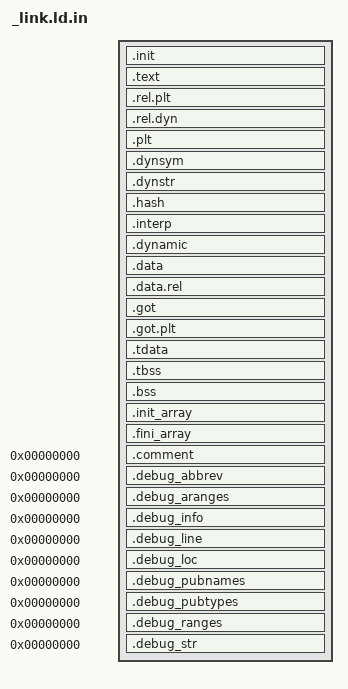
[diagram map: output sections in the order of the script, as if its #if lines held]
#ifndef SHLIB
ENTRY(_start)
#endif

PHDRS {
#if defined(DLEXE)
	interp PT_INTERP;
#endif
	text PT_LOAD FILEHDR PHDRS FLAGS(5);
	data PT_LOAD FLAGS(6);
	tls PT_TLS;
#if defined(SHLIB) || defined(DLEXE)
	dynamic PT_DYNAMIC;
#endif
	debug PT_NOTE;
}

SECTIONS {
#ifdef SHLIB
	. = SEGMENT_START("text-segment", 0);
#else
	. = SEGMENT_START("text-segment", 0x400000);
	PROVIDE (__executable_start = .);
#endif
	. = . + SIZEOF_HEADERS;

	.init : {
		*(.init);
	} :text

	.text : {
		*(.text .text.*);
		*(.rodata .rodata.*);
	} :text

#if defined(SHLIB) || defined(DLEXE)
	.rel.plt : {
		*(.rel.plt);
	}
	/*
	 *.rel.dyn MUST FOLLOW IMMEDIATELY after .rel.plt
	 * without alignment gap or DT_REL will be broken
	 */
	.rel.dyn : {
		*(.rel.*);
	} :text

	.plt : {
		*(.plt);
	} :text

	.dynsym : {
		*(.dynsym);
	} :text

	.dynstr : {
		*(.dynstr);
	} :text

	.hash : {
		*(.hash .gnu.hash);
	} :text
#endif

#if defined(DLEXE)
	.interp : {
		*(.interp);
	} :interp :text
#endif

	. = . + 0x1000;

#if defined(SHLIB) || defined(DLEXE)
	.dynamic : {
		*(.dynamic);
	} :data :dynamic
#endif

	.data : {
		*(.data);
	} :data

#if defined(SHLIB) || defined(DLEXE)
	.data.rel : {
		*(.data.rel .data.rel.*);
	} :data

	.got : {
		*(.got);
	} :data
#endif

	.got.plt : {
		*(.got.plt);
	} :data

	.tdata : {
		*(.tdata);
		*(.tdata.*);
		*(.gnu.linkonce.td.*);
	} :data :tls

	.tbss : {
		*(.tbss);
		*(.tbss.*);
		*(.gnu.linkonce.tb.*);
	} :data :tls

	.bss : {
		*(.dynbss);
		*(COMMON);
		*(.bss);
	} :data

	__dso_handle = .;

	.init_array : {
#ifndef SHLIB
		PROVIDE_HIDDEN (__init_array_start = .);
#endif
		KEEP (*(SORT_BY_INIT_PRIORITY(.init_array.*) SORT_BY_INIT_PRIORITY(.ctors.*)))
		KEEP (*(.init_array .ctors))
#ifndef SHLIB
		PROVIDE_HIDDEN (__init_array_end = .);
#endif
	}

	.fini_array : {
#ifndef SHLIB
		PROVIDE_HIDDEN (__fini_array_start = .);
#endif
		KEEP (*(SORT_BY_INIT_PRIORITY(.fini_array.*) SORT_BY_INIT_PRIORITY(.dtors.*)))
		KEEP (*(.fini_array .dtors))
#ifndef SHLIB
		PROVIDE_HIDDEN (__fini_array_end = .);
#endif
	}

	_end = .;

#ifdef CONFIG_LINE_DEBUG
	.comment 0 : { *(.comment); } :debug
	.debug_abbrev 0 : { *(.debug_abbrev); } :debug
	.debug_aranges 0 : { *(.debug_aranges); } :debug
	.debug_info 0 : { *(.debug_info); } :debug
	.debug_line 0 : { *(.debug_line); } :debug
	.debug_loc 0 : { *(.debug_loc); } :debug
	.debug_pubnames 0 : { *(.debug_pubnames); } :debug
	.debug_pubtypes 0 : { *(.debug_pubtypes); } :debug
	.debug_ranges 0 : { *(.debug_ranges); } :debug
	.debug_str 0 : { *(.debug_str); } :debug
#endif

	/DISCARD/ : {
		*(*);
	}
}
